# SATCAT5 register map
File version: 2.9.0
SatCat5 ConfigBus devices
Registers are 32-bit, read-only, reset 0x0 unless marked. A register's access mark holds for its fields unless they carry their own. Offsets are from the block's base; lines under a group give offsets from that group; [hi:lo] are bit positions; {n}, {i} and the like mark numbered series; 'fields as' and 'values as' point back to an identical list; <NAME> marks a mode.

## Memory map
0x00000000 SWITCH_CORE size 0x1000 — Ethernet switch core
0x00000000 PORT_MAILMAP size 0x1000 — Memory-mapped switch port for the CPU
0x00000000 PORT_STATS size 0x1000 — Per-port traffic statistics
0x00000000 MDIO size 0x1000 — MDIO controller with a command FIFO

## SWITCH_CORE — Ethernet switch core
Base 0x00000000
0x00 PORT_COUNT — Number of ports
0x04 DATA_WIDTH — Datapath width in bits
0x08 CORE_CLOCK — Core clock frequency in Hz
0x0C TABLE_SIZE — MAC-address table size
0x10 PROMISCUOUS rw — Promiscuous port mask, LSB is port 0
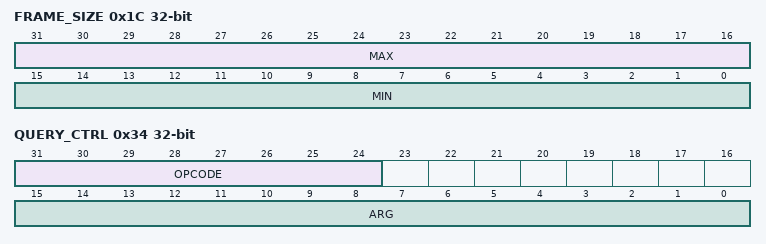
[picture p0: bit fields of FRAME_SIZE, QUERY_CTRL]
0x1C FRAME_SIZE — Frame size limits in bytes
  [31:16] MAX, [15:0] MIN
0x2C QUERY_MAC_LSB rw — MAC-table access: 32 LSBs of the MAC address
0x30 QUERY_MAC_MSB rw — MAC-table access: 16 MSBs of the MAC address
  [15:0] MAC
0x34 QUERY_CTRL rw — MAC-table access: opcode and argument (src/vhdl/common/mac_query.vhd)
  [31:24] OPCODE — Reads back the opcode while busy, zero when done
    0=IDLE; 1=READ; 2=WRITE; 3=CLEAR; 4=LEARN
  [15:0] ARG — Table index or port index; after a read, the port index

## PORT_MAILMAP — Memory-mapped switch port for the CPU
Base 0x00000000
{0x0+4i} RX_DATA[{i}] (i=0..399) — Received frame contents
0x7FC RX_CTRL rw — Read: received frame length, 0 when empty. Write: discard the frame and read the next
{0x800+4i} TX_DATA[{i}] (i=0..399) rw — Transmit frame buffer
0xFFC TX_CTRL rw — Write: frame length to send. Read: 1 while busy

## PORT_STATS — Per-port traffic statistics
Base 0x00000000
{0x0+0x40*i} PORT[{i}] (i=0..63) group — Sixteen registers per port
  0x00 BCAST_BYTES rw — Broadcast bytes received. A write to any register refreshes all counters
  0x04 BCAST_FRAMES — Broadcast frames received
  0x08 RCVD_BYTES — Bytes received from the device
  0x0C RCVD_FRAMES — Frames received from the device
  0x10 SENT_BYTES — Bytes sent to the device
  0x14 SENT_FRAMES — Frames sent to the device
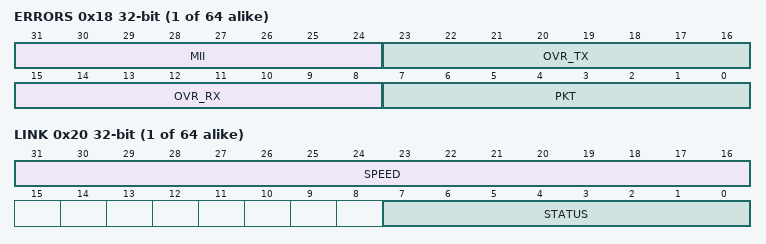
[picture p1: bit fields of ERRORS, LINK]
  0x18 ERRORS — Error counts since the previous refresh
    [31:24] MII — MAC and PHY errors
    [23:16] OVR_TX — Tx-FIFO overflows
    [15:8] OVR_RX — Rx-FIFO overflows
    [7:0] PKT — Packet errors
  0x20 LINK — Link status, read without a refresh
    [31:16] SPEED — Link speed in Mbps
    [7:0] STATUS — Port status word

## MDIO — MDIO controller with a command FIFO
Base 0x00000000
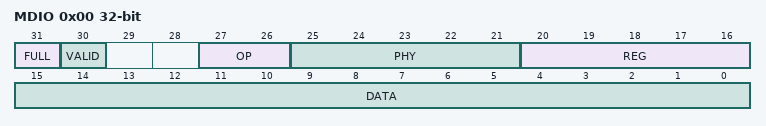
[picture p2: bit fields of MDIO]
0x00 MDIO rw — Write: queue an operation. Read: FIFO status and read data
  [31] FULL ro — Command FIFO is full
  [30] VALID ro — Read data is valid
  [27:26] OP wo
    1=WRITE; 2=READ
  [25:21] PHY wo — PHY address
  [20:16] REG wo — Register address
  [15:0] DATA — Write data, or read data when VALID
